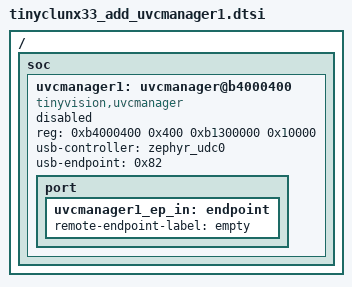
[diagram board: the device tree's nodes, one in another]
/*
 * Copyright (c) 2024 tinyVision.ai Inc.
 *
 * SPDX-License-Identifier: Apache-2.0
 */

/ {
	soc {
		uvcmanager1: uvcmanager@b4000400 {
			compatible = "tinyvision,uvcmanager";
			reg = <0xb4000400 0x400
			       0xb1300000 0x10000>;
			reg-names = "base",
				    "fifo";
			usb-controller = <&zephyr_udc0>;
			usb-endpoint = <0x82>;
			status = "disabled";

			port {
				uvcmanager1_ep_in: endpoint {
					remote-endpoint-label = "empty";
				};
			};
		};
	};
};
